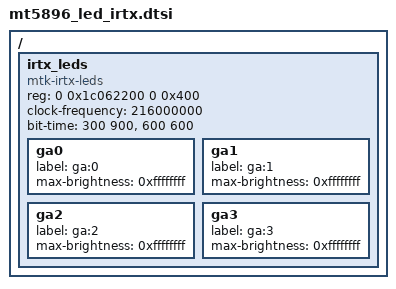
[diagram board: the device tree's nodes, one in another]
// SPDX-License-Identifier: (GPL-2.0 OR BSD-3-Clause)
/*
 * Copyright (c) 2020 MediaTek Inc.
 */

/ {
	irtx_leds: irtx_leds {
		compatible = "mtk-irtx-leds";
		reg = <0 0x1c062200 0 0x400>;
		clock-frequency = <216000000>;
		bit-time = <300 900>,
				<600 600>;
		ga0 {
			label = "ga:0";
			/* brightness = <0>; */ /* default 0 */
			max-brightness = <0xffffffff>;
			/* max-lightness = <100>; */ /* default 100 */
		};

		ga1 {
			label = "ga:1";
			/* brightness = <0>; */ /* default 0 */
			max-brightness = <0xffffffff>;
			/* max-lightness = <100>; */ /* default 100 */
		};

		ga2 {
			label = "ga:2";
			/* brightness = <0>; */ /* default 0 */
			max-brightness = <0xffffffff>;
			/* max-lightness = <100>; */ /* default 100 */
		};

		ga3 {
			label = "ga:3";
			/* brightness = <0>; */ /* default 0 */
			max-brightness = <0xffffffff>;
			/* max-lightness = <100>; */ /* default 100 */
		};
	};
};
